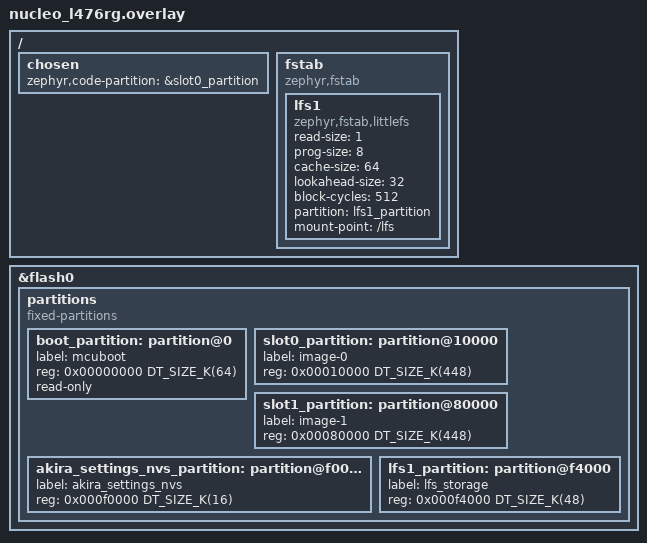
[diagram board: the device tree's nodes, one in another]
/*
 * Nucleo L476RG Device Tree Overlay
 * ST Nucleo board - STM32L476RG (1MB flash)
 */

/*
 * Flash Partition Layout (1MB total):
 * 0x000000 - 0x00FFFF: MCUboot bootloader  (64KB)
 * 0x010000 - 0x07FFFF: Primary slot        (448KB)
 * 0x080000 - 0x0EFFFF: Secondary slot      (448KB)
 * 0x0F0000 - 0x0F3FFF: NVS Settings        (16KB)
 * 0x0F4000 - 0x0FFFFF: LittleFS storage    (48KB)
 */

/ {
	chosen {
		zephyr,code-partition = &slot0_partition;
	};

	fstab {
		compatible = "zephyr,fstab";

		lfs1: lfs1 {
			compatible = "zephyr,fstab,littlefs";
			read-size = <1>;
			prog-size = <8>;
			cache-size = <64>;
			lookahead-size = <32>;
			block-cycles = <512>;
			partition = <&lfs1_partition>;
			mount-point = "/lfs";
		};
	};
};

&flash0 {
	partitions {
		compatible = "fixed-partitions";
		#address-cells = <1>;
		#size-cells = <1>;

		boot_partition: partition@0 {
			label = "mcuboot";
			reg = <0x00000000 DT_SIZE_K(64)>;
			read-only;
		};

		slot0_partition: partition@10000 {
			label = "image-0";
			reg = <0x00010000 DT_SIZE_K(448)>;
		};

		slot1_partition: partition@80000 {
			label = "image-1";
			reg = <0x00080000 DT_SIZE_K(448)>;
		};

		akira_settings_nvs_partition: partition@f0000 {
			label = "akira_settings_nvs";
			reg = <0x000f0000 DT_SIZE_K(16)>;
		};

		lfs1_partition: partition@f4000 {
			label = "lfs_storage";
			reg = <0x000f4000 DT_SIZE_K(48)>;
		};
	};
};
